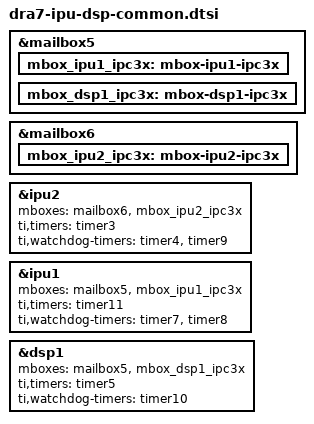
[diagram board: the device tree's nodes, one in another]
// SPDX-License-Identifier: GPL-2.0
/*
 * Common IPU and DSP data for TI DRA7xx/AM57xx platforms
 */

&mailbox5 {
	status = "okay";
	mbox_ipu1_ipc3x: mbox-ipu1-ipc3x {
		status = "okay";
	};
	mbox_dsp1_ipc3x: mbox-dsp1-ipc3x {
		status = "okay";
	};
};

&mailbox6 {
	status = "okay";
	mbox_ipu2_ipc3x: mbox-ipu2-ipc3x {
		status = "okay";
	};
};

&ipu2 {
	mboxes = <&mailbox6 &mbox_ipu2_ipc3x>;
	ti,timers = <&timer3>;
	ti,watchdog-timers = <&timer4>, <&timer9>;
};

&ipu1 {
	mboxes = <&mailbox5 &mbox_ipu1_ipc3x>;
	ti,timers = <&timer11>;
	ti,watchdog-timers = <&timer7>, <&timer8>;
};

&dsp1 {
	mboxes = <&mailbox5 &mbox_dsp1_ipc3x>;
	ti,timers = <&timer5>;
	ti,watchdog-timers = <&timer10>;
};
